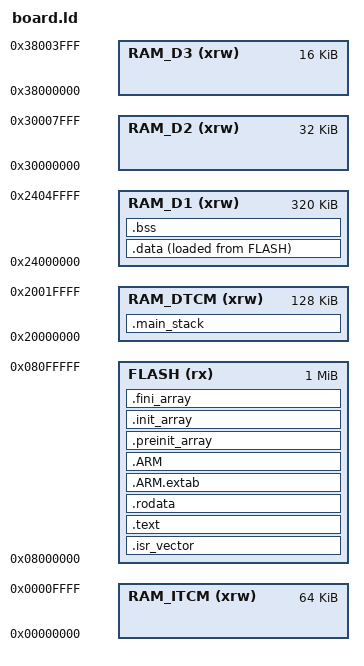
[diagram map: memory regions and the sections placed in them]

/* Entry Point */
ENTRY(Reset_Handler)

/* Specify the memory areas */
MEMORY
{
    RAM_DTCM (xrw)  : ORIGIN = 0x20000000,  LENGTH = 128K
    RAM_D1  (xrw)   : ORIGIN = 0x24000000,  LENGTH = 320K
    RAM_D2  (xrw)   : ORIGIN = 0x30000000,  LENGTH = 32K
    RAM_D3  (xrw)   : ORIGIN = 0x38000000,  LENGTH = 16K
    RAM_ITCM (xrw)  : ORIGIN = 0x00000000,  LENGTH = 64K
    FLASH (rx)      : ORIGIN = 0x8000000,   LENGTH = 1024K
}

_Main_Stack_Size = 0x400; /* required amount of stack */

_sram = ORIGIN(RAM_D2);
_eram = ORIGIN(RAM_D2) + LENGTH(RAM_D2);

/* Define output sections */
SECTIONS
{
  /* The startup code goes first into FLASH */
  .isr_vector :
  {
    . = ALIGN(4);
    KEEP(*(.isr_vector)) /* Startup code */
    . = ALIGN(4);
  } >FLASH

  /* The program code and other data goes into FLASH */
  .text :
  {
    . = ALIGN(4);
    *(.text)           /* .text sections (code) */
    *(.text*)          /* .text* sections (code) */
    *(.glue_7)         /* glue arm to thumb code */
    *(.glue_7t)        /* glue thumb to arm code */
    *(.eh_frame)

    KEEP (*(.init))
    KEEP (*(.fini))

    . = ALIGN(4);
    _etext = .;        /* define a global symbols at end of code */
  } >FLASH

  /* Constant data goes into FLASH */
  .rodata :
  {
    . = ALIGN(4);
    *(.rodata)         /* .rodata sections (constants, strings, etc.) */
    *(.rodata*)        /* .rodata* sections (constants, strings, etc.) */
    . = ALIGN(4);
  } >FLASH

  .ARM.extab (READONLY) : /* The READONLY keyword is only supported in GCC11 and later, remove it if using GCC10 or earlier. */
  {
    *(.ARM.extab* .gnu.linkonce.armextab.*)
  } >FLASH
  .ARM (READONLY) : /* The READONLY keyword is only supported in GCC11 and later, remove it if using GCC10 or earlier. */
  {
    __exidx_start = .;
    *(.ARM.exidx*)
    __exidx_end = .;
  } >FLASH

  .preinit_array (READONLY) : /* The READONLY keyword is only supported in GCC11 and later, remove it if using GCC10 or earlier. */
  {
    PROVIDE_HIDDEN (__preinit_array_start = .);
    KEEP (*(.preinit_array*))
    PROVIDE_HIDDEN (__preinit_array_end = .);
  } >FLASH

  .init_array (READONLY) : /* The READONLY keyword is only supported in GCC11 and later, remove it if using GCC10 or earlier. */
  {
    PROVIDE_HIDDEN (__init_array_start = .);
    KEEP (*(SORT(.init_array.*)))
    KEEP (*(.init_array*))
    PROVIDE_HIDDEN (__init_array_end = .);
  } >FLASH

  .fini_array (READONLY) : /* The READONLY keyword is only supported in GCC11 and later, remove it if using GCC10 or earlier. */
  {
    PROVIDE_HIDDEN (__fini_array_start = .);
    KEEP (*(SORT(.fini_array.*)))
    KEEP (*(.fini_array*))
    PROVIDE_HIDDEN (__fini_array_end = .);
  } >FLASH
  
    /* assign space for main stack */
    .main_stack :
    {
        . = ALIGN(4);
        . = . + _Main_Stack_Size;    /* main stack */
	    . = ALIGN(4);
        _estack = .;        /* a global symbol at MSP end */
    }>RAM_DTCM
    
  /* used by the startup to initialize data */
  _sidata = LOADADDR(.data);

  /* Initialized data sections goes into RAM, load LMA copy after code */
  .data :
  {
    . = ALIGN(4);
    _sdata = .;        /* create a global symbol at data start */
    *(.data)           /* .data sections */
    *(.data*)          /* .data* sections */
    *(.RamFunc)        /* .RamFunc sections */
    *(.RamFunc*)       /* .RamFunc* sections */

    . = ALIGN(4);
    _edata = .;        /* define a global symbol at data end */
  } >RAM_D1 AT> FLASH

  /* Uninitialized data section */
  . = ALIGN(4);
  .bss :
  {
    /* This is used by the startup in order to initialize the .bss section */
    _sbss = .;         /* define a global symbol at bss start */
    __bss_start__ = _sbss;
    *(.bss)
    *(.bss*)
    *(COMMON)

    . = ALIGN(4);
    _ebss = .;         /* define a global symbol at bss end */
    __bss_end__ = _ebss;
  } >RAM_D1

  /* Remove information from the standard libraries */
  /DISCARD/ :
  {
    libc.a ( * )
    libm.a ( * )
    libgcc.a ( * )
  }

  .ARM.attributes 0 : { *(.ARM.attributes) }
}
